# ahbstatMirroredSlave: IP-XACT component
VLNV spiritconsortium.org:Leon2RTL:ahbstatMirroredSlave:1.2

## Bus interfaces (logical=physical port)
AHBClk: slave spiritconsortium.org:busdef.clock:clock:1.0
  CLK=clk
AHBReset: slave spiritconsortium.org:busdef.reset:reset:1.0
  RESETn=rst
ambaAHBMirroredSlaveMonitor: monitor amba.com:AMBA2:AHB:r2p0_6
  HRESP=hresp, HADDR=haddr, HWRITE=hwrite, HREADYOUT=hready, HSIZE=hsize, HMASTER=hmaster, HCLK=clk, HRESETn=rst
ambaAPB: slave amba.com:AMBA2:APB:r2p0_4, memory map ambaAPB
  PSELx=psel, PRDATA=prdata, PWDATA=pwdata, PENABLE=penable, PADDR=paddr, PWRITE=pwrite, PCLK=clk, PRESETn=rst

## Ports
in clk
in rst
in haddr[31:0]
in hwrite
in hready
in hsize[2:0]
in hmaster[3:0]
in hresp[1:0]
out prdata[31:0]
in pwdata[31:0]
in penable
in paddr[31:0]
in pwrite
in psel
out ahberr

## Address spaces and blocks
ambaAPB.defaultid4489951: base 0, range 8, width 32

## Registers
Registers are 32-bit, read-write, reset 0x0 unless marked. A register's access mark holds for its fields unless they carry their own. Offsets are from the block's base; lines under a group give offsets from that group; [hi:lo] are bit positions; {n}, {i} and the like mark numbered series; 'fields as' and 'values as' point back to an identical list; <NAME> marks a mode.

## ambaAPB.defaultid4489951
Base 0x00000000
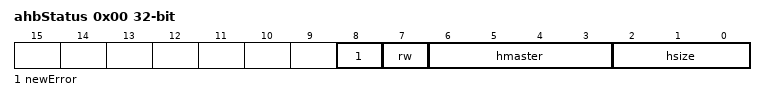
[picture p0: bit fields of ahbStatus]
0x00 ahbStatus — This register is updated whenever and AHB error occurs. The newError bit is set. After an error, the newError bit has to be reset by software.
  [8] newError — Set when a new error occurred.
  [7] rw — This bit is set if the failed access was a read cycle, otherwise it is cleared.
  [6:3] hmaster — This field contains the HMASTER[3:0] of the failed transfer, only if this connected to a slave or mirrored slave.
  [2:0] hsize — This field contains the HSIZE[2:0] of the failed transfer.
0x04 ahbFailedAddress — This register is updated whenever and AHB error occurs. The newError bit is set in register ahbStatus.
  [31:0] haddr — This field contains the HADDR[31:0] of the failed transfer.

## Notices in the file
Copyright (c) 2006, 2008, 2009 The SPIRIT Consortium.
This work forms part of a deliverable of The SPIRIT Consortium.
Use of these materials are governed by the legal terms and conditions
outlined in the disclaimer available from www.spiritconsortium.org.
This source file is provided on an AS IS basis.  The SPIRIT
Consortium disclaims any warranty express or implied including
any warranty of merchantability and fitness for use for a
particular purpose.
The user of the source file shall indemnify and hold The SPIRIT
Consortium and its members harmless from any damages or liability.
